AUTOSAR XML (schema 4-2-2)
package /Components
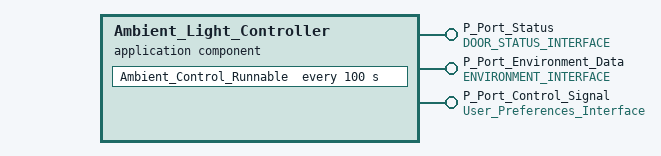
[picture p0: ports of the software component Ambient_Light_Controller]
  application sw component type Ambient_Light_Controller
    provide port P_Port_Status: provided-interface=DOOR_STATUS_INTERFACE
    provide port P_Port_Environment_Data: provided-interface=ENVIRONMENT_INTERFACE
    provide port P_Port_Control_Signal: provided-interface=User_Preferences_Interface
    behavior Ambient_Light_Controller_Behavior: handle-termination-and-restart=true
      init event Init_E: start-on-event=Ambient_Control_Runnable
      timing event Sample_Tick: start-on-event=Ambient_Control_Runnable, period=100
      runnable Ambient_Control_Runnable: can-be-invoked-concurrently=true, symbol=Ambient_Control_Symbol
        data-receive-point-by-values:
          access DoorStatus_Read: accessed-variable=P_Port_Status.ENVIRONMENT_DATA
          access EnvData_Read: accessed-variable=P_Port_Environment_Data.BRIGHTNESS_PRESET
        data-send-points:
          access Control_Signal_Send: accessed-variable=P_Port_Control_Signal.PREFERRED_MODE
